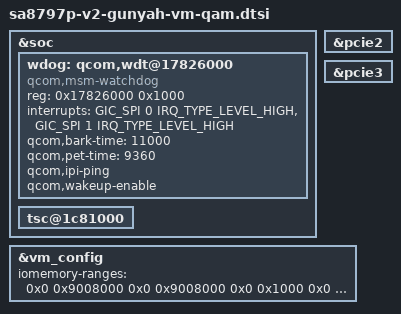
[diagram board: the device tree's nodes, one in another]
// SPDX-License-Identifier: BSD-3-Clause
/*
 * Copyright (c) Qualcomm Technologies, Inc. and/or its subsidiaries.
 */

#include "sa8797p-gunyah-vm-qam.dtsi"

&soc {
	wdog: qcom,wdt@17826000 {
		compatible = "qcom,msm-watchdog";
		reg = <0x17826000 0x1000>;
		reg-names = "wdt-base";
		interrupts = <GIC_SPI 0 IRQ_TYPE_LEVEL_HIGH>,
			<GIC_SPI 1 IRQ_TYPE_LEVEL_HIGH>;
		qcom,bark-time = <11000>;
		qcom,pet-time = <9360>;
		qcom,ipi-ping;
		qcom,wakeup-enable;
	};

	tsc@1c81000 {
		status = "ok";
	};
};

&pcie2 {
	ranges = <0x01000000 0x0 0x60000000 0x0 0x60000000 0x0 0x100000>,
		<0x02000000 0x0 0x60100000 0x0 0x60100000 0x0 0x7000000>,
		<0x43000000 0x40 0x10100000 0x40 0x10100000 0x0 0x100000>;
};

&pcie3 {
	ranges = <0x01000000 0x0 0x70000000 0x0 0x70000000 0x0 0x100000>,
		<0x02000000 0x0 0x70100000 0x0 0x70100000 0x0 0x7000000>,
		<0x43000000 0x4 0x10100000 0x4 0x10100000 0x0 0x100000>;
};

&vm_config {
	/* Pass through regions */
	iomemory-ranges = <
		/* MPROC NS1 IPCC region */
		0x0 0x9008000 0x0 0x9008000 0x0 0x1000 0x0
		/* QUPv3 Tile 2 read-only region */
		0x0 0x8C0000 0x0 0x8C0000 0x0 0x2000 0x1
		/* QUPv3 SE14 region */
		0x0 0x880000 0x0 0x880000 0x0 0x3000 0x0
		/* QUPv3 SE17 region */
		0x0 0x88C000 0x0 0x88C000 0x0 0x3000 0x0
		/* USB2 region */
		0x0 0x88e0000 0x0 0x88e0000 0x0 0x1000 0x0
		0x0 0xa200000 0x0 0xa200000 0x0 0x200000 0x0
		/* PCIE2 regions */
		0x40 0x0 0x40 0x0 0x0 0x10000000 0x0
		0x0 0x60000000 0x0 0x60000000 0x0 0x100000 0x0
		0x0 0x60100000 0x0 0x60100000 0x0 0x7000000 0x0
		0x40 0x10100000 0x40 0x10100000 0x0 0x100000 0x0
		/* TLMM region */
		0x0 0xF000000 0x0 0xF000000 0x0 0x1000000 0x0
		/* QRNG region */
		0x0 0x10cd000 0x0 0x10cd000 0x0 0x1000 0x0
		/* EMAC 1 DWC region */
		0x0 0x1A80000 0x0 0x1A80000 0x0 0x1A000 0x0
		/* EMAC 1 IO CSR region */
		0x0 0x1AFF000 0x0 0x1AFF000 0x0 0x1000 0x0
		/* GPU_0_GMU region */
		0x0 0x3D40000 0x0 0x3D40000 0x0 0x1000 0x0
		/* GPU_1_GMU region */
		0x0 0x9840000 0x0 0x9840000 0x0 0x1000 0x0
		/* PDC region */
		0x0 0xb220000 0x0 0xb220000 0x0 0x10000 0x0
		/* VCODEC CS1 region */
		0x0 0xAAA1000 0x0 0xAAA1000 0x0 0x1000 0x0
		/* USB1 region */
		0x0 0x88eb000 0x0 0x88eb000 0x0 0x1000 0x0
		0x0 0x88e4000 0x0 0x88e4000 0x0 0x3000 0x0
		0x0 0xa400000 0x0 0xa400000 0x0 0x200000 0x0
		/* PCIE3 regions */
		0x4 0x0 0x4 0x0 0x0 0x10000000 0x0
		0x0 0x70000000 0x0 0x70000000 0x0 0x100000 0x0
		0x0 0x70100000 0x0 0x70100000 0x0 0x7000000 0x0
		0x4 0x10100000 0x4 0x10100000 0x0 0x100000 0x0
		/* Fence NS1 IPCC region */
		0x0 0x9307000 0x0 0x9307000 0x0 0x1000 0x0
		/* Board serial number region */
		0x0 0x360D4000 0x0 0x360D4000 0x0 0x1000 0x1
		/* TSC Region */
		0x0 0x1C81000 0x0 0x1C81000 0x0 0x1000 0x1
		/* Imem region */
		0x0 0x14680000 0x0 0x14680000 0x0 0x1000 0x0
		0x0 0xc221000 0x0 0xc221000 0x0 0x1000 0x1
		/* SDHC4 region */
		0x0 0x00b84000 0x0 0x00b84000 0x0 0x1000 0x0
	>;
};
